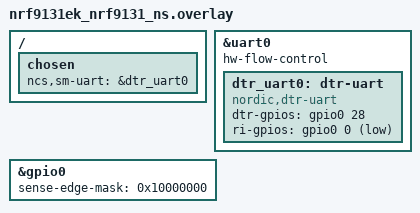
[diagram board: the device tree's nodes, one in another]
/*
 * Copyright (c) 2024 Nordic Semiconductor ASA
 *
 * SPDX-License-Identifier: LicenseRef-Nordic-5-Clause
 */

/ {
	chosen {
		ncs,sm-uart = &dtr_uart0;
	};
};

&uart0 {
	status = "okay";
	hw-flow-control;

	dtr_uart0: dtr-uart {
		compatible = "nordic,dtr-uart";
		dtr-gpios = <&gpio0 28 (GPIO_PULL_UP | GPIO_ACTIVE_HIGH)>;
		ri-gpios = <&gpio0 0 GPIO_ACTIVE_LOW>;
		status = "okay";
	};
};

&gpio0 {
	status = "okay";
	/* Use PORT event for DTR (28) pin to save power */
	sense-edge-mask = <0x10000000>;
};
